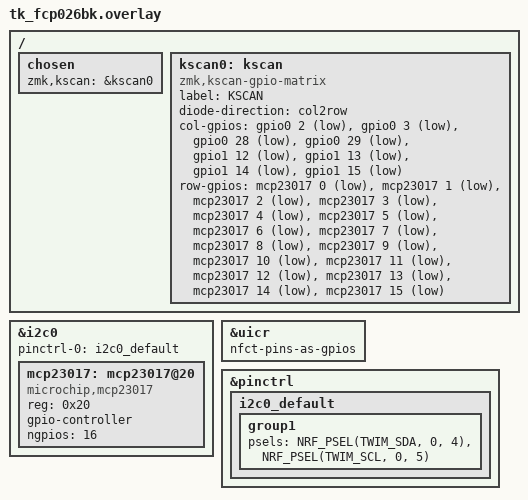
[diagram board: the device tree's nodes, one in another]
/*
 * TK-FCP026BK Shield Overlay v5
 * XIAO nRF52840 + MCP23017
 *
 * 新配線:
 *   Col 0-7 : XIAO GPIO D0-D3, D5-D10
 *             D0=Col0, D1=Col1, D2=Col2, D3=Col3,
 *             D7=Col4, D8=Col5, D9=Col6, D10=Col7  ※D4はI2C(SDA)
 *   Row 0-15: MCP23017 GPA0-7(Row0-7) + GPB0-7(Row8-15)
 *
 * ダイオードなしマトリクス:
 *   diode-direction = "col2row"
 *   Col: OUTPUT (GPIO_ACTIVE_LOW)
 *   Row: INPUT  (GPIO_ACTIVE_LOW | GPIO_PULL_UP)
 */
#include "keymaps/tk_fcp026bk.keymap"

&i2c0 {
    status = "okay";
    pinctrl-0 = <&i2c0_default>;
    pinctrl-names = "default";
    mcp23017: mcp23017@20 {
        compatible = "microchip,mcp23017";
        reg = <0x20>;
        gpio-controller;
        #gpio-cells = <2>;
        ngpios = <16>;
        status = "okay";
    };
};

/* P0.28/P0.29 (D2/D3) をNFCピンからGPIOとして使用するための設定 */
&uicr {
    nfct-pins-as-gpios;
};

&pinctrl {
    i2c0_default: i2c0_default {
        group1 {
            psels = <NRF_PSEL(TWIM_SDA, 0, 4)>,
                    <NRF_PSEL(TWIM_SCL, 0, 5)>;
        };
    };
};

/ {
    chosen {
        zmk,kscan = &kscan0;
    };

    kscan0: kscan {
        compatible = "zmk,kscan-gpio-matrix";
        label = "KSCAN";
        diode-direction = "col2row";

        col-gpios
            = <&gpio0 2  GPIO_ACTIVE_LOW>  /* Col0 D0  P0.02 */
            , <&gpio0 3  GPIO_ACTIVE_LOW>  /* Col1 D1  P0.03 */
            , <&gpio0 28 GPIO_ACTIVE_LOW>  /* Col2 D2  P0.28 */
            , <&gpio0 29 GPIO_ACTIVE_LOW>  /* Col3 D3  P0.29 */
            , <&gpio1 12 GPIO_ACTIVE_LOW>  /* Col4 D7  P1.12 */
            , <&gpio1 13 GPIO_ACTIVE_LOW>  /* Col5 D8  P1.13 */
            , <&gpio1 14 GPIO_ACTIVE_LOW>  /* Col6 D9  P1.14 */
            , <&gpio1 15 GPIO_ACTIVE_LOW>  /* Col7 D10 P1.15 */
            ;

        row-gpios
            = <&mcp23017 0  (GPIO_ACTIVE_LOW | GPIO_PULL_UP)>  /* Row0  GPA0 */
            , <&mcp23017 1  (GPIO_ACTIVE_LOW | GPIO_PULL_UP)>  /* Row1  GPA1 */
            , <&mcp23017 2  (GPIO_ACTIVE_LOW | GPIO_PULL_UP)>  /* Row2  GPA2 */
            , <&mcp23017 3  (GPIO_ACTIVE_LOW | GPIO_PULL_UP)>  /* Row3  GPA3 */
            , <&mcp23017 4  (GPIO_ACTIVE_LOW | GPIO_PULL_UP)>  /* Row4  GPA4 */
            , <&mcp23017 5  (GPIO_ACTIVE_LOW | GPIO_PULL_UP)>  /* Row5  GPA5 */
            , <&mcp23017 6  (GPIO_ACTIVE_LOW | GPIO_PULL_UP)>  /* Row6  GPA6 */
            , <&mcp23017 7  (GPIO_ACTIVE_LOW | GPIO_PULL_UP)>  /* Row7  GPA7 */
            , <&mcp23017 8  (GPIO_ACTIVE_LOW | GPIO_PULL_UP)>  /* Row8  GPB0 */
            , <&mcp23017 9  (GPIO_ACTIVE_LOW | GPIO_PULL_UP)>  /* Row9  GPB1 */
            , <&mcp23017 10 (GPIO_ACTIVE_LOW | GPIO_PULL_UP)>  /* Row10 GPB2 */
            , <&mcp23017 11 (GPIO_ACTIVE_LOW | GPIO_PULL_UP)>  /* Row11 GPB3 */
            , <&mcp23017 12 (GPIO_ACTIVE_LOW | GPIO_PULL_UP)>  /* Row12 GPB4 */
            , <&mcp23017 13 (GPIO_ACTIVE_LOW | GPIO_PULL_UP)>  /* Row13 GPB5 */
            , <&mcp23017 14 (GPIO_ACTIVE_LOW | GPIO_PULL_UP)>  /* Row14 GPB6 */
            , <&mcp23017 15 (GPIO_ACTIVE_LOW | GPIO_PULL_UP)>  /* Row15 GPB7 */
            ;
    };
};
